# MCXN947_cm33_core0 register map
Vendor: nxp.com; File version: 1.0
CPU: CM33 r2p0, little endian, MPU, FPU, VTOR, 3 interrupt priority bits
Registers are 32-bit, read-write, reset 0x0 unless marked. A register's access mark holds for its fields unless they carry their own. Offsets are from the block's base; [hi:lo] are bit positions; {n}, {i} and the like mark numbered series; 'fields as' and 'values as' point back to an identical list.

## SAI0 — SAI
Base 0x40106000
Same registers: SAI1 0x40107000
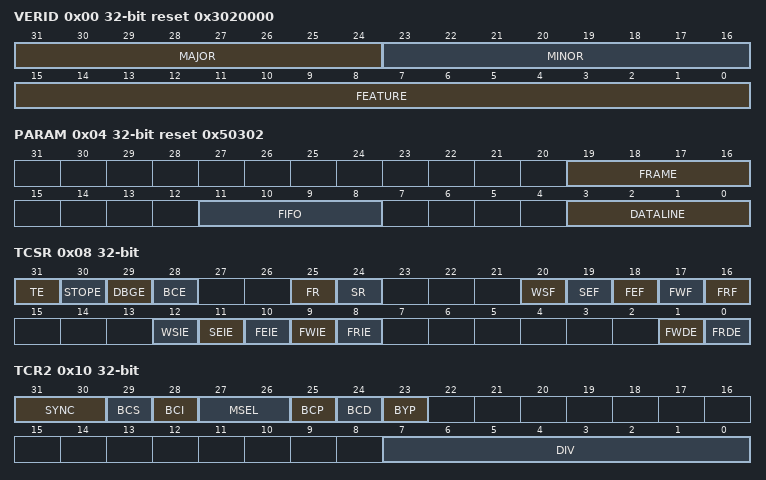
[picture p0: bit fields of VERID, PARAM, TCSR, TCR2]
0x00 VERID ro reset 0x3020000 — Version ID
  [31:24] MAJOR — Major Version Number
  [23:16] MINOR — Minor Version Number
  [15:0] FEATURE — Feature Specification Number
    0=STD (Standard feature set.)
0x04 PARAM ro reset 0x50302 — Parameter
  [19:16] FRAME — Frame Size
  [11:8] FIFO — FIFO Size
  [3:0] DATALINE — Number of Datalinks
0x08 TCSR — Transmit Control
  [31] TE — Transmitter Enable
    0=DISABLE (Transmitter is disabled.); 1=ENABLE (Transmitter is enabled, or transmitter has been disabled and has not yet reached end of frame.)
  [30] STOPE — Stop Enable
    0=DISABLE (Transmitter disabled in Stop mode.); 1=ENABLE (Transmitter enabled in Stop mode.)
  [29] DBGE — Debug Enable
    0=DISABLE (Transmitter is disabled in Debug mode, after completing the current frame.); 1=ENABLE (Transmitter is enabled in Debug mode.)
  [28] BCE — Bit Clock Enable
    0=DISABLE (Transmit bit clock is disabled.); 1=ENABLE (Transmit bit clock is enabled.)
  [25] FR — FIFO Reset
    0=NO_EFFECT; 1=RESET (FIFO reset.)
  [24] SR — Software Reset
    0=DISABLE (No effect); 1=ENABLE (Software reset)
  [20] WSF write-1-clears — Word Start Flag
    0=NO_FLAG (Start of word not detected.); 1=FLAG (Start of word detected.)
  [19] SEF write-1-clears — Sync Error Flag
    0=NO_FLAG (Sync error not detected.); 1=FLAG (Frame sync error detected.)
  [18] FEF write-1-clears — FIFO Error Flag
    0=NO_FLAG (Transmit underrun not detected.); 1=FLAG (Transmit underrun detected.)
  [17] FWF ro — FIFO Warning Flag
    0=DISABLE (No enabled transmit FIFO is empty.); 1=ENABLE (Enabled transmit FIFO is empty.)
  [16] FRF ro — FIFO Request Flag
    0=NO_FLAG (Transmit FIFO watermark has not been reached.); 1=FLAG (Transmit FIFO watermark has been reached.)
  [12] WSIE — Word Start Interrupt Enable
    0=DISABLE (Disables interrupt.); 1=ENABLE (Enables interrupt.)
  [11] SEIE — Sync Error Interrupt Enable
    values as WSIE
  [10] FEIE — FIFO Error Interrupt Enable
    0=DISABLE (Disables the interrupt.); 1=ENABLE (Enables the interrupt.)
  [9] FWIE — FIFO Warning Interrupt Enable
    values as FEIE
  [8] FRIE — FIFO Request Interrupt Enable
    values as FEIE
  [1] FWDE — FIFO Warning DMA Enable
    0=DISABLE (Disables the DMA warning.); 1=ENABLE (Enables the DMA warning.)
  [0] FRDE — FIFO Request DMA Enable
    0=DISABLE (Disables the DMA request.); 1=ENABLE (Enables the DMA request.)
0x0C TCR1 — Transmit Configuration 1
  [2:0] TFW — Transmit FIFO Watermark
    0=MIN (1 FIFO word); 1=TWO (2 FIFO words); {v}=WATERMARK_VALUE_{v} ((TFW +1) FIFO words) (v=2..6); 7=MAX (8 FIFO words)
0x10 TCR2 — Transmit Configuration 2
  [31:30] SYNC — Synchronous Mode
    0=ASYNC (Asynchronous mode); 1=SYNC_W_RX (Synchronous with receiver); 2=SYNC_W_TX (Synchronous with another SAI transmitter); 3=SYNC_W_ANOTHER_SAI_RX (Synchronous with another SAI receiver)
  [29] BCS — Bit Clock Swap
    0=DISABLE (Use the normal bit clock source.); 1=ENABLE (Swap the bit clock source.)
  [28] BCI — Bit Clock Input
    0=DISABLE (No effect.); 1=ENABLE (Internal logic is clocked as if bit clock was externally generated.)
  [27:26] MSEL — MCLK Select
    0=BUS_CLOCK (Bus Clock selected.); 1=MCLK1 (Master Clock (MCLK) 1 option selected.); 2=MCLK2 (Master Clock (MCLK) 2 option selected.); 3=MCLK3 (Master Clock (MCLK) 3 option selected.)
  [25] BCP — Bit Clock Polarity
    0=ACTIVE_HIGH (Bit clock is active high with drive outputs on rising edge and sample inputs on falling edge.); 1=ACTIVE_LOW (Bit clock is active low with drive outputs on falling edge and sample inputs on rising edge.)
  [24] BCD — Bit Clock Direction
    0=EXT_IN_SLAVE (Bit clock is generated externally in Slave mode.); 1=INT_IN_MASTER (Bit clock is generated internally in Master mode.)
  [23] BYP — Bit Clock Bypass
    0=DISABLE (Internal bit clock is generated from bit clock divider.); 1=ENABLE (Internal bit clock is divide-by-one of the audio master clock.)
  [7:0] DIV — Bit Clock Divide
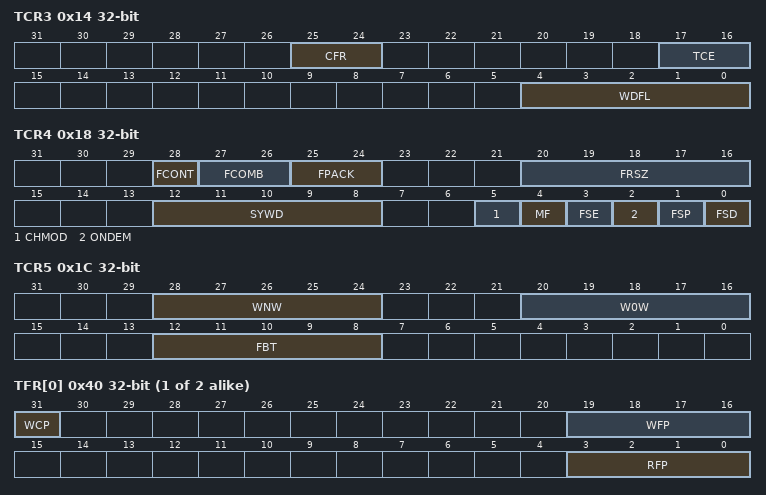
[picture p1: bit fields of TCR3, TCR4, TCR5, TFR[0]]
0x14 TCR3 — Transmit Configuration 3
  [25:24] CFR — Channel FIFO Reset
  [17:16] TCE — Transmit Channel Enable
  [4:0] WDFL — Word Flag Configuration
0x18 TCR4 — Transmit Configuration 4
  [28] FCONT — FIFO Continue on Error
    0=DISABLE (On FIFO error, SAI continues from the start of the next frame after the FIFO error flag has been cleared.); 1=ENABLE (On FIFO error, SAI continues from the same word that caused the FIFO error to become 1 after the FIFO warning flag returns to 0.)
  [27:26] FCOMB — FIFO Combine Mode
    0=DISABLED (FIFO Combine mode disabled.); 1=ENABLED_ON_FIFO_READS (FIFO Combine mode enabled on FIFO reads (from transmit shift registers).); 2=ENABLED_ON_FIFO_WRITES (FIFO Combine mode enabled on FIFO writes (by software).); 3=ENABLED_ON_FIFO_READS_WRITES (FIFO Combine mode enabled on FIFO reads (from transmit shift registers) and writes (by software).)
  [25:24] FPACK — FIFO Packing Mode
    0=DISABLED (FIFO packing is disabled.); 2=EIGHT_BIT_FIFO_PACKING (8-bit FIFO packing is enabled.); 3=SIXTEEN_BIT_FIFO_PACKING (16-bit FIFO packing is enabled.)
  [20:16] FRSZ — Frame size
  [12:8] SYWD — Sync Width
  [5] CHMOD — Channel Mode
    0=TDM_MODE (TDM mode, transmit data pins are 3-stated when slots are masked or channels are disabled.); 1=OUTPUT_MODE (Output mode, transmit data pins are never 3-stated and output zero when slots are masked or channels are disabled.)
  [4] MF — MSB First
    0=DISABLE (LSB is transmitted first.); 1=ENABLE (MSB is transmitted first.)
  [3] FSE — Frame Sync Early
    0=DISABLE (Frame sync asserts with the first bit of the frame.); 1=ENABLE (Frame sync asserts one bit before the first bit of the frame.)
  [2] ONDEM — On Demand Mode
    0=CONTINUOUS_FRAME_SYNC (Internal frame sync is generated continuously.); 1=ON_DEMAND_FRAME_SYNC (Internal frame sync is generated when the FIFO warning flag is 0.)
  [1] FSP — Frame Sync Polarity
    0=ACTIVE_HIGH (Frame sync is active high.); 1=ACTIVE_LOW (Frame sync is active low.)
  [0] FSD — Frame Sync Direction
    0=EXT_IN_SLAVE_MODE (Frame sync is generated externally in Slave mode.); 1=INT_IN_MASTER_MODE (Frame sync is generated internally in Master mode.)
0x1C TCR5 — Transmit Configuration 5
  [28:24] WNW — Word N Width
    7=EIGHT (8 bits per word); 8=NINE (9 bits per word); {v}=TEN_THIRTYONE_{v} ((WNW value + 1) bits per word) (v=9..16); 31=MAX (32 bits per word)
  [20:16] W0W — Word 0 Width
    7=EIGHT (8 bits per word); 8=NINE (9 bits per word); {v}=TEN_THIRTYONE_{v} ((W0W value + 1) bits per word) (v=9..16); 31=MAX (32 bits per word)
  [12:8] FBT — First Bit Shifted
    0=INDEX0 (Bit index is 0.); {v}=INDEX_{v} (Bit index is FBT value.) (v=1..9); 31=INDEX31 (Bit index is 31.)
{0x20+4i} TDR[{i}] (i=0..1) — Transmit Data
  [31:0] TDR — Transmit Data Register
{0x40+4i} TFR[{i}] (i=0..1) ro — Transmit FIFO
  [31] WCP — Write Channel Pointer
    0=DISABLE (No effect); 1=ENABLE (FIFO Combine mode is enabled for FIFO writes and this FIFO will be written on the next FIFO write.)
  [19:16] WFP — Write FIFO Pointer
  [3:0] RFP — Read FIFO Pointer
0x60 TMR — Transmit Mask
  [31:0] TWM — Transmit Word Mask
    0=WORD_N_ENABLED (Word N is enabled.); 1=WORD_N_MASKED (Word N is masked. The transmit data pins are 3-stated or drive zero when masked.)
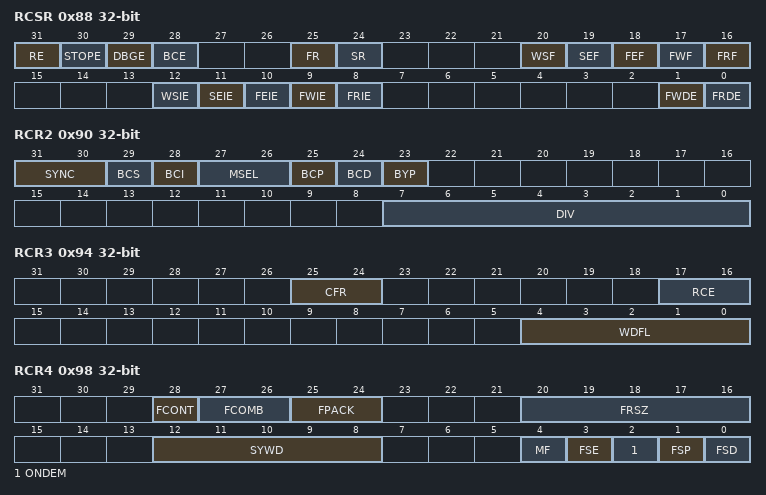
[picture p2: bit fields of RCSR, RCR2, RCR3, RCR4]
0x88 RCSR — Receive Control
  [31] RE — Receiver Enable
    0=DISABLE (Receiver is disabled.); 1=ENABLE (Receiver is enabled, or receiver has been disabled and has not yet reached end of frame.)
  [30] STOPE — Stop Enable
    0=DISABLE (Receiver disabled in Stop mode.); 1=ENABLE (Receiver enabled in Stop mode.)
  [29] DBGE — Debug Enable
    0=DISABLE (Receiver is disabled in Debug mode, after completing the current frame.); 1=ENABLE (Receiver is enabled in Debug mode.)
  [28] BCE — Bit Clock Enable
    0=DISABLE (Receive bit clock is disabled.); 1=ENABLE (Receive bit clock is enabled.)
  [25] FR — FIFO Reset
    0=NO_EFFECT; 1=FIFO_RESET
  [24] SR — Software Reset
    0=NO_EFFECT; 1=SW_RESET (Software reset.)
  [20] WSF write-1-clears — Word Start Flag
    values as TCSR.WSF
  [19] SEF write-1-clears — Sync Error Flag
    values as TCSR.SEF
  [18] FEF write-1-clears — FIFO Error Flag
    0=NO_FLAG (Receive overflow not detected.); 1=FLAG (Receive overflow detected.)
  [17] FWF ro — FIFO Warning Flag
    0=NOT_FULL (No enabled receive FIFO is full.); 1=FULL (Enabled receive FIFO is full.)
  [16] FRF ro — FIFO Request Flag
    0=BELOW_WATERMARK (Receive FIFO watermark not reached.); 1=WATERMARK_REACHED (Receive FIFO watermark has been reached.)
  [12] WSIE — Word Start Interrupt Enable
    values as TCSR.WSIE
  [11] SEIE — Sync Error Interrupt Enable
    values as TCSR.WSIE
  [10] FEIE — FIFO Error Interrupt Enable
    values as TCSR.FEIE
  [9] FWIE — FIFO Warning Interrupt Enable
    values as TCSR.FEIE
  [8] FRIE — FIFO Request Interrupt Enable
    values as TCSR.FEIE
  [1] FWDE — FIFO Warning DMA Enable
    0=DISABLE (Disables DMA warnings.); 1=ENABLE (Enables DMA warnings.)
  [0] FRDE — FIFO Request DMA Enable
    values as TCSR.FRDE
0x8C RCR1 — Receive Configuration 1
  [2:0] RFW — Receive FIFO Watermark
    0=MIN (1 FIFO word); 1=TWO (2 FIFO words); {v}=WATERMARK_{v} ((RFW value + 1) FIFO words) (v=2..6); 7=MAX (8 FIFO words)
0x90 RCR2 — Receive Configuration 2
  [31:30] SYNC — Synchronous Mode
    0=Asynchronous mode; 1=SYNC_W_TX (Synchronous with transmitter); 2=SYNC_W_ANOTHER_SAI_RX (Synchronous with another SAI receiver); 3=SYNC_W_ANOTHER_SAI_TX (Synchronous with another SAI transmitter)
  [29] BCS — Bit Clock Swap
    0=NORMAL (Use the normal bit clock source.); 1=SWAP_BIT_CLK_SOURCE (Swap the bit clock source.)
  [28] BCI — Bit Clock Input
    0=NO_EFFECT; 1=CLOCKED_AS_IF_EXT_GENERATED (Internal logic is clocked as if bit clock was externally generated.)
  [27:26] MSEL — MCLK Select
    values as TCR2.MSEL
  [25] BCP — Bit Clock Polarity
    values as TCR2.BCP
  [24] BCD — Bit Clock Direction
    0=EXT_SLAVE_MODE (Bit clock is generated externally in Slave mode.); 1=INT_MASTER_MODE (Bit clock is generated internally in Master mode.)
  [23] BYP — Bit Clock Bypass
    values as TCR2.BYP
  [7:0] DIV — Bit Clock Divide
0x94 RCR3 — Receive Configuration 3
  [25:24] CFR — Channel FIFO Reset
  [17:16] RCE — Receive Channel Enable
  [4:0] WDFL — Word Flag Configuration
    0=WORD_1; 1=WORD_2; {v}=WORD_N_{v} (Word (WDFL value + 1)) (v=2..9); 31=WORD_MAX (Word 32)
0x98 RCR4 — Receive Configuration 4
  [28] FCONT — FIFO Continue on Error
    0=DISABLE (On FIFO error, SAI continues from the start of the next frame after the FIFO error flag returns to 0.); 1=ENABLE (On FIFO error, SAI continues from the same word that caused the FIFO error to become 1 after the FIFO warning flag returns to 0.)
  [27:26] FCOMB — FIFO Combine Mode
    0=DISABLED (FIFO Combine mode disabled.); 1=ENA_ON_FIFO_WRITES (FIFO Combine mode enabled on FIFO writes (from receive shift registers).); 2=ENA_ON_FIFO_READS (FIFO Combine mode enabled on FIFO reads (by software).); 3=ENA_ON_FIFO_WRITES_READS (FIFO Combine mode enabled on FIFO writes (from receive shift registers) and reads (by software).)
  [25:24] FPACK — FIFO Packing Mode
    0=DISABLED (FIFO packing is disabled); 2=EIGHT_BIT_PACKING (8-bit FIFO packing is enabled); 3=SIXTEEN_BIT_PACKING (16-bit FIFO packing is enabled)
  [20:16] FRSZ — Frame Size
    0=ONE_WORD (1 word per frame); 1=TWO_WORDS (2 words per frame); {v}=N_WORDS_{v} ((FRSZ value + 1) words per frame) (v=2..9); 31=MAX_WORDS (32 words per frame)
  [12:8] SYWD — Sync Width
    0=MIN (1 bit-clock cycle); 1=TWO_CLOCKS (2 bit-clock cycle); {v}=N_CLOCKS_{v} ((SYWD value + 1) bit-clock cycle) (v=2..9); 31=THIRTYTWO_CLOCKS (32 bit-clock cycle)
  [4] MF — MSB First
    0=DISABLE (LSB is received first.); 1=ENABLE (MSB is received first.)
  [3] FSE — Frame Sync Early
    values as TCR4.FSE
  [2] ONDEM — On Demand Mode
    0=DISABLE (Internal frame sync is generated continuously.); 1=ENABLE (Internal frame sync is generated when the FIFO warning flag is 0.)
  [1] FSP — Frame Sync Polarity
    values as TCR4.FSP
  [0] FSD — Frame Sync Direction
    0=EXT_SLAVE_MODE (Frame Sync is generated externally in Slave mode.); 1=INT_MASTER_MODE (Frame Sync is generated internally in Master mode.)
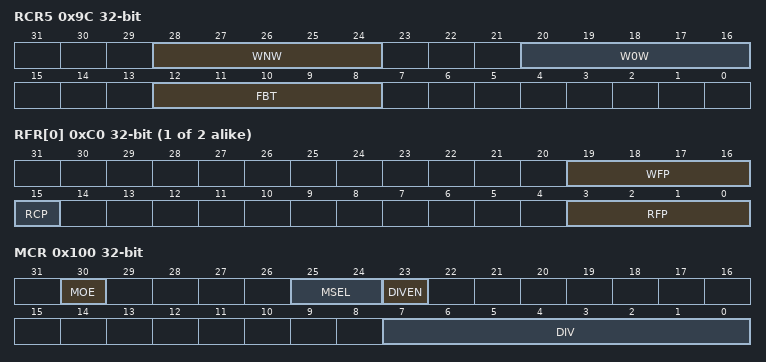
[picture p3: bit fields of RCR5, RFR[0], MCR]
0x9C RCR5 — Receive Configuration 5
  [28:24] WNW — Word N Width
    values as TCR5.WNW
  [20:16] W0W — Word 0 Width
    0=MIN (1 bit per word); 1=TWO (2 bits per word); {v}=THREE_THIRTYONE_{v} ((W0W value + 1) bits per word) (v=2..9); 31=MAX (32 bits per word)
  [12:8] FBT — First Bit Shifted
    values as TCR5.FBT
{0xA0+4i} RDR[{i}] (i=0..1) ro — Receive Data
  [31:0] RDR — Receive Data Register
{0xC0+4i} RFR[{i}] (i=0..1) ro — Receive FIFO
  [19:16] WFP — Write FIFO Pointer
  [15] RCP — Receive Channel Pointer
    0=DISABLE (No effect.); 1=ENABLE (FIFO Combine mode is enabled for FIFO reads and this FIFO will be read on the next FIFO read.)
  [3:0] RFP — Read FIFO Pointer
0xE0 RMR — Receive Mask
  [31:0] RWM — Receive Word Mask
    0=WORD_N_ENABLED (Word N is enabled.); 1=WORD_N_MASKED (Word N is masked.)
0x100 MCR — MCLK Control
  [30] MOE — MCLK Output Enable
    0=INPUT (MCLK signal pin is an input.); 1=OUTPUT (MCLK signal pin is an output.)
  [25:24] MSEL — MCLK Select
    0=MCLK1 (Master Clock (MCLK) 1 option selected.); 2=MCLK2 (Master Clock (MCLK) 2 option selected.); 3=MCLK3 (Master Clock (MCLK) 3 option selected.)
  [23] DIVEN — MCLK Post Divide Enable
    0=DISABLE (Output on MCLK signal pin is the audio master clock.); 1=ENABLE (Output on MCLK signal pin is a post-divided version of audio master clock.)
  [7:0] DIV — MCLK Post Divide
